# PIC32MK0512GPK100 device description
Architecture: MIPS; Family: PIC32MK; Series: PIC32MK
Registers are 32-bit, read-write, no defined reset value unless marked. A register's access mark holds for its fields unless they carry their own. Offsets are from the block's base; [hi:lo] are bit positions; {n}, {i} and the like mark numbered series; 'fields as' and 'values as' point back to an identical list.

## FUSECONFIG
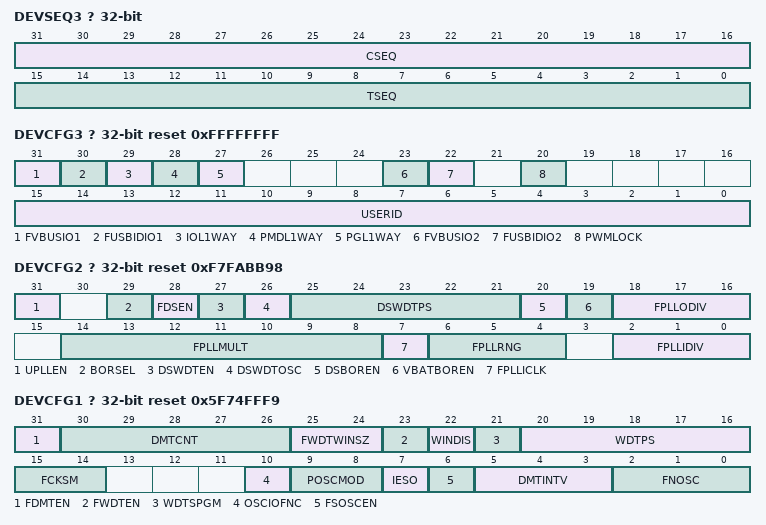
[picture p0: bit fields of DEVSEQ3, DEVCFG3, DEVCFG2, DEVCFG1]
? DEVSEQ3 size not given access not given
  [31:16] CSEQ — Boot Flash Complement Sequence Number bits
    ?=Boot Flash Complement Sequence Number
  [15:0] TSEQ — Boot Flash True Sequence Number bits
    ?=Boot Flash True Sequence Number
? DEVCFG3 size not given access not given reset 0xFFFFFFFF — Device Configuration Word 3
  [31] FVBUSIO1 — USB1 VBUSON Selection bit
    1=ON (VBUSON pin is controlled by the USB1 module); 0=OFF (VBUSON pin is controlled by the port function)
  [30] FUSBIDIO1 — USB1 USBID Selection bit
    1=ON (USBID pin is controlled by the USB1 module); 0=OFF (USBID pin is controlled by the port function)
  [29] IOL1WAY — Peripheral Pin Select Configuration bit
    1=ON (Allow only one reconfiguration); 0=OFF (Allow multiple reconfigurations)
  [28] PMDL1WAY — Peripheral Module Disable Configuration bit
    values as IOL1WAY
  [27] PGL1WAY — Permission Group Lock One Way Configuration bit
    values as IOL1WAY
  [23] FVBUSIO2 — USB2 VBUSON Selection bit
    1=ON (VBUSON pin is controlled by the USB2 module); 0=OFF (VBUSON pin is controlled by the port function)
  [22] FUSBIDIO2 — USB2 USBID Selection bit
    1=ON (USBID pin is controlled by the USB2 module); 0=OFF (USBID pin is controlled by the port function)
  [20] PWMLOCK — PWM Write Access Select bit
    0=ON (PWM IOxCON register write accesses must use the PWMKEY unlock procedure); 1=OFF (PWM IOxCON register writes accesses are not locked or protected)
  [15:0] USERID
    ?=User ID
? DEVCFG2 size not given access not given reset 0xF7FABB98 — Device Configuration Word 2
  [31] UPLLEN — USB PLL Enable bit
    1=OFF (USB PLL Disabled); 0=ON (USB PLL Enabled)
  [29] BORSEL — Brown-out Reset Select Trip Voltage bit
    1=HIGH (BOR trip voltage 2.1v (Non-OPAMP deviced operation)); 0=LOW (BOR trip voltage 2.8v (OPAMP deviced operation))
  [28] FDSEN — Deep Sleep Bit Enable bit
    0=OFF (Disable DSEN bit in DSCON); 1=ON (Enable DSEN bit in DSCON)
  [27] DSWDTEN — Deep Sleep Watchdog Timer Enable bit
    0=OFF (Disable DSWDT during Deep Sleep Mode); 1=ON (Enable DSWDT during Deep Sleep Mode)
  [26] DSWDTOSC — Deep Sleep Watchdog Timer Reference Clock Select bit
    0=SOSC (Select SOSC as DSWDT Reference Clock); 1=LPRC (Select LPRC as DSWDT Reference clock)
  [25:21] DSWDTPS — Deep Sleep Watchdog Timer Postscale Select bits
    {v}=DSPS{v+1} (1:2^{v+5}) (v=0..31)
  [20] DSBOREN — Deep Sleep Zero-Power BOR Enable bit
    0=OFF (Disable ZPBOR during Deep Sleep Mode); 1=ON (Enable ZPBOR during Deep Sleep Mode)
  [19] VBATBOREN — VBAT Zero-Power BOR Enable bit
  [18:16] FPLLODIV — Default System PLL Output Divisor bits
    1=DIV_2 (PLL output divided by 2); 2=DIV_4 (PLL output divided by 4); 3=DIV_8 (PLL output divided by 8); 4=DIV_16 (PLL output divided by 16); 7=DIV_32 (PLL output divided by 32)
  [14:8] FPLLMULT — System PLL Feedback Divider bits
    {v}=MUL_{v+1} (PLL Multiply by {v+1}) (v=0..127)
  [7] FPLLICLK — System PLL Input Clock Select bit
    1=PLL_FRC (FRC is input to the System PLL); 0=PLL_POSC (POSC is input to the System PLL)
  [6:4] FPLLRNG — System PLL Divided Input Clock Frequency Range bits
    0=RANGE_BYPASS (Bypass); 1=RANGE_5_10_MHZ (5-10 MHz Input); 2=RANGE_8_16_MHZ (8-16 MHz Input); 3=RANGE_13_26_MHZ (13-26 MHz Input); 4=RANGE_21_42_MHZ (21-42 MHz Input); 5=RANGE_34_64_MHZ (34-64 MHz Input)
  [2:0] FPLLIDIV — PLL Input Divider bits
    {v}=DIV_{v+1} ({v+1}x Divider) (v=0..7)
? DEVCFG1 size not given access not given reset 0x5F74FFF9 — Device Configuration Word 1
  [31] FDMTEN — Deadman Timer enable bit
    1=ON (Deadman Timer is enabled and cannot be disabled by software); 0=OFF (Deadman Timer is disabled and can be enabled by software)
  [30:26] DMTCNT — Deadman Timer Count Select bits
    0=DMT8 (2^8 (256)); 1=DMT9 (2^9 (512)); 2=DMT10 (2^10 (1024)); 3=DMT11 (2^11 (2048)); 4=DMT12 (2^12 (4096)); 5=DMT13 (2^13 (8192)); 6=DMT14 (2^14 (16384)); 7=DMT15 (2^15 (32768)); 8=DMT16 (2^16 (65536)); 9=DMT17 (2^17 (131072)); 10=DMT18 (2^18 (262144)); 11=DMT19 (2^19 (524288)); 12=DMT20 (2^20 (1048576)); 13=DMT21 (2^21 (2097152)); 14=DMT22 (2^22 (4194304)); 15=DMT23 (2^23 (8388608)); 16=DMT24 (2^24 (16777216)); 17=DMT25 (2^25 (33554432)); 18=DMT26 (2^26 (67108864)); 19=DMT27 (2^27 (134217728)); 20=DMT28 (2^28 (268435456)); 21=DMT29 (2^29 (536870912)); 22=DMT30 (2^30 (1073741824)); 23=DMT31 (2^31 (2147483648))
  [25:24] FWDTWINSZ — Watchdog Timer Window Size bits
    3=WINSZ_25 (Window size is 25%); 2=WINSZ_37 (Window size is 37.5%); 1=WINSZ_50 (Window size is 50%); 0=WINSZ_75 (Window size is 75%)
  [23] FWDTEN — Watchdog Timer Enable bit
    1=ON (WDT Enabled); 0=OFF (WDT Disabled)
  [22] WINDIS — Watchdog Timer Window Enable bit
    1=NORMAL (Watchdog Timer is in non-Window mode); 0=WINDOW (Watchdog Timer is in Window mode)
  [21] WDTSPGM — Watchdog Timer Stop During Flash Programming bit
    0=RUN (WDT runs during Flash programming); 1=STOP (WDT stops during Flash programming)
  [20:16] WDTPS — Watchdog Timer Postscale Select bits
    0=PS1 (1:1); 1=PS2 (1:2); 2=PS4 (1:4); 3=PS8 (1:8); 4=PS16 (1:16); 5=PS32 (1:32); 6=PS64 (1:64); 7=PS128 (1:128); 8=PS256 (1:256); 9=PS512 (1:512); 10=PS1024 (1:1024); 11=PS2048 (1:2048); 12=PS4096 (1:4096); 13=PS8192 (1:8192); 14=PS16384 (1:16384); 15=PS32768 (1:32768); 16=PS65536 (1:65536); 17=PS131072 (1:131072); 18=PS262144 (1:262144); 19=PS524288 (1:524288); 20=PS1048576 (1:1048576)
  [15:14] FCKSM — Clock Switching and Monitoring Selection Configuration bits
    0=CSDCMD (Clock Switch Disabled, FSCM Disabled); 1=CSECMD (Clock Switch Enabled, FSCM Disabled); 2=CSDCME (Clock Switch Disabled, FSCM Enabled); 3=CSECME (Clock Switch Enabled, FSCM Enabled)
  [10] OSCIOFNC — CLKO Enable Configuration bit
    0=ON (CLKO output signal is active on the OSC2 pin); 1=OFF (CLKO output is disabled)
  [9:8] POSCMOD — Primary Oscillator Configuration bits
    0=EC (External clock mode); 2=HS (HS osc mode); 3=OFF (Primary osc disabled)
  [7] IESO — Internal External Switchover bit
    1=ON (Enabled); 0=OFF (Disabled)
  [6] FSOSCEN — Secondary Oscillator Enable bit
    1=ON (Enable Secondary Oscillator); 0=OFF (Disable Secondary Oscillator)
  [5:3] DMTINTV — Deadman Timer Count Window Interval bits
    0=WIN_0 (Window/Interval value is zero); 1=WIN_1_2 (Window/Interval value is 1/2 counter value); 2=WIN_3_4 (Window/Interval value is 3/4 counter value); 3=WIN_7_8 (Window/Interval value is 7/8 counter value); 4=WIN_15_16 (Window/Interval value is 15/16 counter value); 5=WIN_31_32 (Window/Interval value is 31/32 counter value); 6=WIN_63_64 (Window/Interval value is 63/64 counter value); 7=WIN_127_128 (Window/Interval value is 127/128 counter value)
  [2:0] FNOSC — Oscillator Selection bits
    0=FRC (Internal Fast RC (FRC)); 1=SPLL (System PLL); 2=POSC (Primary Osc (HS,EC)); 3=UPLL (USB PLL (UPLL)); 4=SOSC (Low Power Secondary Osc (SOSC)); 5=LPRC (Low Power RC Osc (LPRC)); 6=BFRC (Backup Fast RC (BFRC) Oscillator)
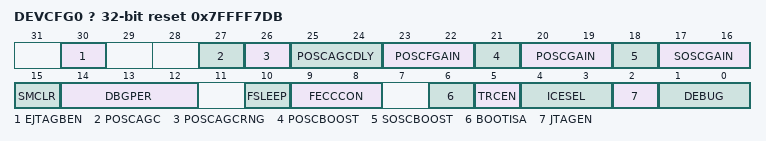
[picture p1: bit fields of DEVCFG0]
? DEVCFG0 size not given access not given reset 0x7FFFF7DB — Device Configuration Word 0
  [30] EJTAGBEN — EJTAG Boot Enable bit
    0=REDUCED (Reduced EJTAG functionality); 1=NORMAL (Normal EJTAG functionality)
  [27] POSCAGC — Primary Oscillator Automatic Gain Control bit
    1=Automatic Gain Control for Oscillator; 0=Manual Gain Control of Oscillator
  [26] POSCAGCRNG — Primary Crystal Oscillator AGC Lock Range bit
    1=ONE_X (Range 1x); 0=FIVE_X (Range 5x)
  [25:24] POSCAGCDLY — Primary Crystal AGC Gain Search Step Settling Time Control bits
    3=AGCRNG_x_25ms (Settling time = 25ms x AGCRNG); 2=AGCRNG_x_6_25ms (Settling time = 6.25ms x AGCRNG); 1=AGCRNG_x_400ms (Settling time = 400ms x AGCRNG); 0=AGCRNG_x_100ms (Settling time = 100ms x AGCRNG)
  [23:22] POSCFGAIN — Primary Crystal Oscillator Fine Gain Control bits
    3=G3 (Gain is G3 (default)); 2=G2 (Gain is G2); 1=G1 (Gain is G1); 0=G0 (Gain is G0)
  [21] POSCBOOST — Primary Oscillator Boost bit
    1=ON (Boost the kick start of the oscillator); 0=OFF (Normal start of the oscillator)
  [20:19] POSCGAIN — Primary Crystal Oscillator Course Gain Control bits
    3=G3 (Gain Level 3 (highest)); 2=G2 (Gain Level 2); 1=G1 (Gain Level 1); 0=G0 (Gain Level 0 (Lowest))
  [18] SOSCBOOST — Secondary Oscillator Kick Start Programmability bit
    values as POSCBOOST
  [17:16] SOSCGAIN — Secondary Oscillator Gain Control bits
    {v}=G{v} (Gain is G{v}) (v=0..3)
  [15] SMCLR — Soft Master Clear Enable bit
    0=MCLR_POR (MCLR pin generates a POR Reset); 1=MCLR_NORM (MCLR pin generates a normal system Reset)
  [14:12] DBGPER — Debug Mode CPU Access Permission
    4=ALLOW_PG2 (Allow CPU access to Permission Group 2 permission regions); 2=ALLOW_PG1 (Allow CPU access to Permission Group 1 permission regions); 1=ALLOW_PG0 (Allow CPU access to Permission Group 0 permission regions); 3=PG_1_0 (PG0: Allow PG1: Allow PG2: Deny); 5=PG_2_0 (PG0: Allow PG1: Deny PG2: Allow); 6=PG_2_1 (PG0: Deny PG1: Allow PG2: Allow); 7=PG_ALL (Allow CPU access to all permission regions); 0=PG_NONE (Deny CPU access to all permission regions)
  [10] FSLEEP — Flash Sleep Mode bit
    0=VREGS (Flash power down is controlled by the VREGS bit); 1=OFF (Flash is powered down when the device is in Sleep mode)
  [9:8] FECCCON — Dynamic Flash ECC Configuration bits
    3=ECC_DECC_DISABLE_ECCON_WRITABLE (ECC and Dynamic ECC are disabled (ECCCON(1-0) bits are writable)); 2=ECC_DECC_DISABLE_ECCON_LOCKED (ECC and Dynamic ECC are disabled (ECCCON(1-0) bits are locked)); 1=DECC_ENABLE (Dynamic Flash ECC is enabled (ECCCON(1-0) bits are locked)); 0=ECC_ENABLE (Flash ECC is enabled (ECCCON(1-0) bits are locked; disables word Flash writes))
  [6] BOOTISA — Boot ISA Selection bit
    1=MIPS32 (Boot code and Exception code is MIPS32); 0=MICROMIPS (Boot code and Exception code is microMIPS)
  [5] TRCEN — Trace Enable bit
    1=ON (Trace features in the CPU are enabled); 0=OFF (Trace features in the CPU are disabled)
  [4:3] ICESEL — In-Circuit Emulator/Debugger Communication Channel Select bits
    3=ICS_PGx1 (Communicate on PGEC1/PGED1); 2=ICS_PGx2 (Communicate on PGEC2/PGED2); 1=ICS_PGx3 (Communicate on PGEC3/PGED3)
  [2] JTAGEN — JTAG Enable bit
    1=ON (JTAG Port Enabled); 0=OFF (JTAG Disabled)
  [1:0] DEBUG — Background Debugger Enable bits
    0=ON (Debugger is enabled); 3=OFF (Debugger is disabled)
Value list DEVCFG4__A1DIFFPR: 3=USE_PMOS_NMOS (Uses Both PMOS and NMOS Differential Pair); 2=USE_NMOS (Uses NMOS Differential Pair); 1=USE_PMOS (Use PMOS Differential Pair)
Value list DEVCP__CP: 0=ON (Protection Enabled); 1=OFF (Protection Disabled)

## Notices in the file
Copyright (c) 2019 Microchip Technology Inc.
SPDX-License-Identifier: Apache-2.0
Licensed under the Apache License, Version 2.0 (the "License");
you may not use this file except in compliance with the License.
You may obtain a copy of the License at
http://www.apache.org/licenses/LICENSE-2.0
Unless required by applicable law or agreed to in writing, software
distributed under the License is distributed on an "AS IS" BASIS,
WITHOUT WARRANTIES OR CONDITIONS OF ANY KIND, either express or implied.
See the License for the specific language governing permissions and
limitations under the License.
